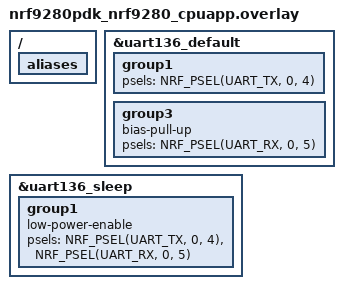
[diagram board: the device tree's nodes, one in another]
/ {
	/* Delete these aliases because the button nodes are deleted. */
	aliases {
		/delete-property/ sw0;
		/delete-property/ sw1;
	};
};

/* Remove buttons because they conflict with modem pin allocations. */
/delete-node/ &button0;
/delete-node/ &button1;

&uart136_default {
	group1 {
		psels = <NRF_PSEL(UART_TX, 0, 4)>;
	};
	group3 {
		bias-pull-up;
		psels = <NRF_PSEL(UART_RX, 0, 5)>;
	};
};
&uart136_sleep {
	group1 {
		low-power-enable;
		psels = <NRF_PSEL(UART_TX, 0, 4)>,
			<NRF_PSEL(UART_RX, 0, 5)>;
	};
};
